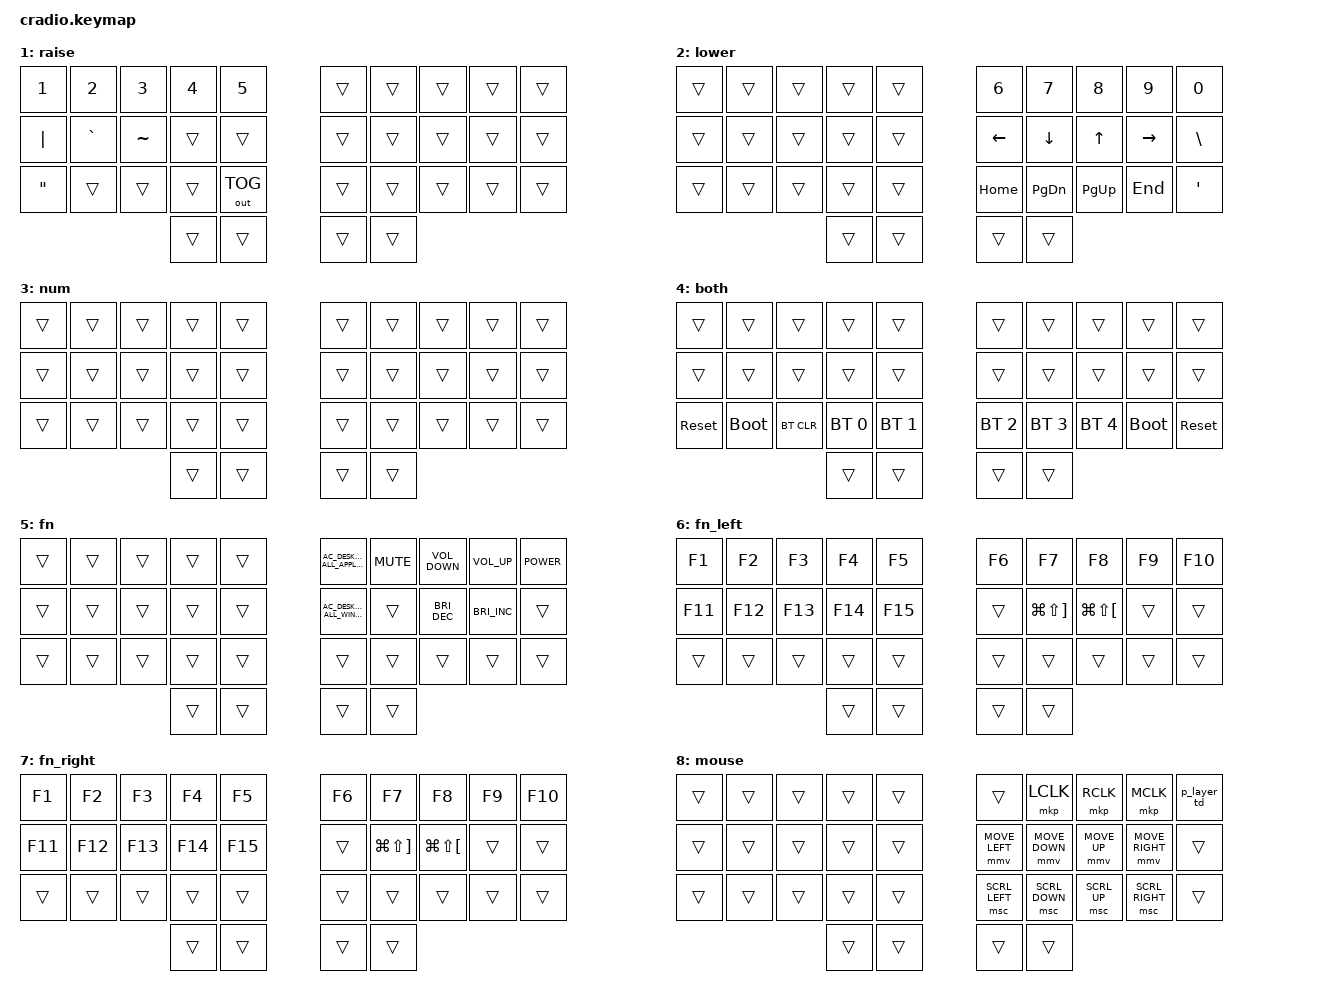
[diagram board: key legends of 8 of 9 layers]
// Copyright (c) 2022 The ZMK Contributors
// SPDX-License-Identifier: MIT


#define ZMK_POINTING_DEFAULT_MOVE_VAL 1500  // default: 600
#define ZMK_POINTING_DEFAULT_SCRL_VAL 20    // default: 10

#include <behaviors.dtsi>
#include <behaviors/mouse_keys.dtsi>
#include <dt-bindings/zmk/keys.h>
#include <dt-bindings/zmk/bt.h>
#include <dt-bindings/zmk/pointing.h>
#include <dt-bindings/zmk/outputs.h>

// Home row mods macro
#define HRML(k1,k2,k3,k4) &ht LSHFT k1  &ht LALT k2  &ht LCTRL k3  &ht LGUI k4
#define HRMR(k1,k2,k3,k4) &ht RGUI k1  &ht RCTRL k2  &ht RALT k3  &ht RSHFT k4

/ {
    combos {
        compatible = "zmk,combos";

        esc {
            timeout-ms = <50>;
            key-positions = <0 1>;
            bindings = <&kp ESC>;
        };

        esc_2 {
            timeout-ms = <50>;
            key-positions = <1 2>;
            bindings = <&kp ESC>;
        };

        backspace_or_delete {
            timeout-ms = <50>;
            key-positions = <7 8>;
            bindings = <&backspace_or_delete>;
        };

        tab {
            timeout-ms = <50>;
            key-positions = <11 12>;
            bindings = <&kp TAB>;
        };

        parenopenorless {
            timeout-ms = <50>;
            key-positions = <16 17>;
            bindings = <&paren_or_less_than>;
        };

        parencloseorgreater {
            timeout-ms = <50>;
            key-positions = <17 18>;
            bindings = <&paren_or_greather_than>;
        };

        copy {
            timeout-ms = <50>;
            key-positions = <21 22>;
            bindings = <&kp LG(C)>;
        };

        paste {
            timeout-ms = <50>;
            key-positions = <22 23>;
            bindings = <&kp LG(V)>;
        };
        
        cut {
            timeout-ms = <50>;
            key-positions = <21 23>;
            bindings = <&kp LG(X)>;
        };

        paste_maccy {
            timeout-ms = <50>;
            key-positions = <21 22 23>;
            bindings = <&kp LG(LS(C))>;
        };

        lbkt_or_lbrc {
            timeout-ms = <50>;
            key-positions = <26 27>;
            bindings = <&lbkt_or_lbrc>;
        };

        rbkt_or_rbrc {
            timeout-ms = <50>;
            key-positions = <27 28>;
            bindings = <&rbkt_or_rbrc>;
        };

        admiracion {
            timeout-ms = <50>;
            key-positions = <0 10>;
            bindings = <&kp EXCL>;
        }; 

        arroba {
            timeout-ms = <50>;
            key-positions = <1 11>;
            bindings = <&kp AT>;
        }; 

        michi {
            timeout-ms = <50>;
            key-positions = <2 12>;
            bindings = <&kp HASH>;
        }; 

        dollar {
            timeout-ms = <50>;
            key-positions = <3 13>;
            bindings = <&kp DLLR>;
        }; 

        percent {
            timeout-ms = <50>;
            key-positions = <4 14>;
            bindings = <&kp PRCNT>;
        }; 

        circun {
            timeout-ms = <50>;
            key-positions = <5 15>;
            bindings = <&kp CARET>;
        }; 

        plus {
            timeout-ms = <50>;
            key-positions = <6 16>;
            bindings = <&kp PLUS>;
        }; 

        asterisk {
            timeout-ms = <50>;
            key-positions = <7 17>;
            bindings = <&kp STAR>;
        }; 

        ampersand {
            timeout-ms = <50>;
            key-positions = <8 18>;
            bindings = <&kp AMPS>;
        }; 



        toggle_layer_mouse {
            timeout-ms = <50>;
            key-positions = <8 9>;
            bindings = <&tog 8>;
        }; 

        toggle_layer_num {
            timeout-ms = <50>;
            key-positions = <28 29>;
            bindings = <&tog 3>;
        };


        grave {
            timeout-ms = <50>;
            key-positions = <11 21>;
            bindings = <&kp GRAVE>;
        }; 
        backslash {
            timeout-ms = <50>;
            key-positions = <12 22>;
            bindings = <&kp BSLH>;
        }; 
        equal {
            timeout-ms = <50>;
            key-positions = <13 23>;
            bindings = <&kp EQUAL>;
        }; 
        virgulilla {
            timeout-ms = <50>;
            key-positions = <14 24>;
            bindings = <&kp TILDE>;
        }; 
        underscore {
            timeout-ms = <50>;
            key-positions = <15 25>;
            bindings = <&kp UNDER>;
        }; 
        minus {
            timeout-ms = <50>;
            key-positions = <16 26>;
            bindings = <&kp MINUS>;
        }; 
        slash {
            timeout-ms = <50>;
            key-positions = <17 27>;
            bindings = <&kp SLASH>;
        }; 
        pipe {
            timeout-ms = <50>;
            key-positions = <17 27>;
            bindings = <&kp BSLH>;
        }; 
        

        parentesis_angles_combo {
            timeout-ms = <50>;
            key-positions = <16 17 18>;
            bindings = <&paren_or_less_than_full>;
        };

        bracket_llaves_combo {
            timeout-ms = <50>;
            key-positions = <26 27 28>;
            bindings = <&lbkt_or_lbrc_full>;
        };

        caps_word {
            timeout-ms = <50>;
            key-positions = <14 15>;
            bindings = <&caps_word>;
        };

        leader_leader_s {
            timeout-ms = <50>;
            bindings = <&leader_leader_s>;
            key-positions = <13 16>;
        };

        cmd_shift {
            timeout-ms = <50>;
            bindings = <&kp LS(LGUI)>;
            key-positions = <10 30>;
        };
    };

    macros {
        leader_leader_s: leader_leader {
            compatible = "zmk,behavior-macro";
            #binding-cells = <0>;
            bindings = <&kp ESCAPE &kp SPACE &kp SPACE &kp S>;
            label = "LEADER_LEADER";
        };

        parentesis_full: parentesis_full {
            compatible = "zmk,behavior-macro";
            #binding-cells = <0>;
            bindings = <&kp LPAR &kp RPAR>;
            label = "PARENTESIS_FULL";
        };

        less_greater_full: less_greater_full {
            compatible = "zmk,behavior-macro";
            #binding-cells = <0>;
            bindings = <&kp LT &kp GT>;
            label = "LESS_GREATER_FULL";
        };

        llaves_full: llaves_full {
            compatible = "zmk,behavior-macro";
            #binding-cells = <0>;
            bindings = <&kp LBRC &kp RBRC>;
            label = "LLAVES_FULL";
        };

        corchetes_full: corchetes_full {
            compatible = "zmk,behavior-macro";
            #binding-cells = <0>;
            bindings = <&kp LBKT &kp RBKT>;
            label = "CORCHETES_FULL";
        };
    };

    
    behaviors {
        ht: hold_tap {
            compatible = "zmk,behavior-hold-tap";
            #binding-cells = <2>;
            flavor = "tap-preferred";
            tapping-term-ms = <220>;
            quick-tap-ms = <150>;
            require-prior-idle-ms = <100>;
            bindings = <&kp>, <&kp>;
        };
        ht2: hold_tap_2 {
            compatible = "zmk,behavior-hold-tap";
            #binding-cells = <2>;
            flavor = "tap-preferred";
            tapping-term-ms = <220>;
            quick-tap-ms = <150>;
            require-prior-idle-ms = <100>;
            bindings = <&sl>, <&kp>;
        };
        
        ht2hold: hold_tap_2_hold_preferred {
            compatible = "zmk,behavior-hold-tap";
            #binding-cells = <2>;
            flavor = "hold-preferred";
            tapping-term-ms = <220>;
            quick-tap-ms = <150>;
            require-prior-idle-ms = <100>;
            bindings = <&sl>, <&kp>;
        };

        paren_or_less_than: paren_or_less_than {
            #binding-cells = <0>;
            compatible = "zmk,behavior-mod-morph";
            label = "PAREN_OR_LESS_THAN";
            bindings = <&kp LPAR>, <&kp LT>;
            mods = <(MOD_LSFT | MOD_RSFT)>;
        };

        paren_or_greather_than: paren_or_greather_than {
            #binding-cells = <0>;
            compatible = "zmk,behavior-mod-morph";
            label = "PAREN_OR_GREATHER_THAN";
            bindings = <&kp RPAR>, <&kp GT>;
            mods = <(MOD_LSFT | MOD_RSFT)>;
        };

        lbkt_or_lbrc: lbkt_or_lbrc {
            #binding-cells = <0>;
            compatible = "zmk,behavior-mod-morph";
            label = "lbkt_or_lbrc";
            bindings = <&kp LBKT>, <&kp LBRC>;
            mods = <(MOD_LSFT | MOD_RSFT)>;
        };

        rbkt_or_rbrc: rbkt_or_rbrc {
            #binding-cells = <0>;
            compatible = "zmk,behavior-mod-morph";
            label = "rbkt_or_rbrc";
            bindings = <&kp RBKT>, <&kp RBRC>;
            mods = <(MOD_LSFT | MOD_RSFT)>;
        };
        
        
        paren_or_less_than_full: paren_or_less_than_full {
            #binding-cells = <0>;
            compatible = "zmk,behavior-mod-morph";
            label = "PAREN_OR_LESS_THAN_FULL";
            bindings = <&parentesis_full>, <&less_greater_full>;
            mods = <(MOD_LSFT | MOD_RSFT)>;
        };
        
        lbkt_or_lbrc_full: lbkt_or_lbrc_full {
            #binding-cells = <0>;
            compatible = "zmk,behavior-mod-morph";
            label = "lbkt_or_lbrc_full";
            bindings = <&corchetes_full>, <&llaves_full>;
            mods = <(MOD_LSFT | MOD_RSFT)>;
        };

        backspace_or_delete: backspace_or_delete {
            compatible = "zmk,behavior-mod-morph";
            #binding-cells = <0>;
            bindings = <&kp BACKSPACE>, <&kp DELETE>;
            mods = <(MOD_LSFT|MOD_RSFT)>;
            keep-mods = <(MOD_RSFT)>;
        };

        p_layer_td: p_layer_td {
            compatible = "zmk,behavior-tap-dance";
            label = "P_LAYER_TD";
            #binding-cells = <0>;
            tapping-term-ms = <200>; // Tiempo en ms para detectar el doble toque. Ajusta si es necesario.
            bindings = <&kp P>, <&tog 8>; // <un toque>, <dos toques>
        };
    };

    conditional_layers {
        compatible = "zmk,conditional-layers";
        tri_layer {
            if-layers = <6 7>;
            then-layer = <4>;
        };
    };

    keymap {
        compatible = "zmk,keymap";
        default_layer {
            bindings = <
        //╭──────────┬──────────┬──────────┬──────────┬──────────╮   ╭──────────┬──────────┬──────────┬──────────┬──────────╮
        //│  Q       │  W       │  E       │  R       │  T       │   │  Y       │  U       │  I       │  O       │  P       │
            &kp Q      &kp W      &kp E      &kp R      &kp T          &kp Y      &kp U      &kp I      &kp O      &kp P
        //├──────────┼──────────┼──────────┼──────────┼──────────┤   ├──────────┼──────────┼──────────┼──────────┼──────────┤
        //│  A       │  S       │  D       │  F       │  G       │   │  H       │  J       │  K       │  L       │ ; :      │
            HRML(A,        S,         D,         F)     &kp G          &kp H      HRMR(J,     K,         L,        SEMI)
        //├──────────┼──────────┼──────────┼──────────┼──────────┤   ├──────────┼──────────┼──────────┼──────────┼──────────┤
        //│  Z       │  X       │  C       │  V       │  B       │   │  N       │  M       │ , <      │ . >      │ / ?      │
            &ht2hold 6 Z      &kp X   &kp C      &kp V      &kp B          &kp N      &kp M      &kp COMMA  &ht2 5 DOT  &ht2hold 7 FSLH
        //╰──────────┴──────────┴──────────┼──────────┼──────────┤   ├──────────┼──────────┼──────────┴──────────┴──────────╯
                                            &kp TAB   &sl 1   &ht2hold 2 ENTER  &kp SPACE 
        //                                 ╰──────────┴──────────╯   ╰──────────┴──────────╯
            >;
        };

        raise {
        bindings = <
            &kp NUMBER_1  &kp NUMBER_2  &kp NUMBER_3  &kp NUMBER_4  &kp NUMBER_5     &trans     &trans     &trans    &trans    &trans
            &kp PIPE      &kp GRAVE     &kp TILDE     &trans        &trans           &trans     &trans     &trans    &trans    &trans
            &kp DOUBLE_QUOTES     &trans        &trans        &trans        &out OUT_TOG           &trans     &trans     &trans    &trans    &trans
                                                      &trans        &trans           &trans     &trans
        >;
        };

        lower {
        bindings = <
            &trans   &trans  &trans  &trans  &trans    &kp NUMBER_6    &kp NUMBER_7    &kp NUMBER_8  &kp NUMBER_9     &kp NUMBER_0
            &trans   &trans  &trans  &trans  &trans    &kp LEFT_ARROW  &kp DOWN_ARROW  &kp UP_ARROW  &kp RIGHT_ARROW  &kp BSLH
            &trans   &trans  &trans  &trans  &trans    &kp HOME        &kp PG_DN       &kp PG_UP     &kp END          &kp APOS
                                     &trans  &trans    &trans          &trans
        >;
        };

        num {
        bindings = <
            &trans   &trans   &trans   &trans   &trans   &trans  &trans            &trans            &trans  &trans
            &trans   &trans   &trans   &trans   &trans   &trans  &trans            &trans            &trans  &trans
            &trans   &trans   &trans   &trans   &trans   &trans  &trans            &trans            &trans  &trans
                                             &trans     &trans    &trans     &trans
        >;
        };
        
        both {
        bindings = <
            &trans      &trans        &trans      &trans        &trans        &trans        &trans        &trans        &trans       &trans
            &trans      &trans        &trans      &trans        &trans        &trans        &trans        &trans        &trans       &trans
            &sys_reset  &bootloader   &bt BT_CLR  &bt BT_SEL 0  &bt BT_SEL 1  &bt BT_SEL 2  &bt BT_SEL 3  &bt BT_SEL 4  &bootloader  &sys_reset
                                                                &trans        &trans        &trans        &trans
        >;
        };

        fn {
        bindings = <
            &trans   &trans  &trans  &trans  &trans    &kp C_AC_DESKTOP_SHOW_ALL_APPLICATIONS  &kp C_MUTE            &kp C_VOLUME_DOWN     &kp C_VOLUME_UP        &kp C_POWER
            &trans   &trans  &trans  &trans  &trans    &kp C_AC_DESKTOP_SHOW_ALL_WINDOWS       &trans                &kp C_BRIGHTNESS_DEC  &kp C_BRIGHTNESS_INC  &trans
            &trans   &trans  &trans  &trans  &trans    &trans                                  &trans                &trans                &trans  &trans
                                     &trans  &trans    &trans                                  &trans
        >;
        };

        //special {
        //bindings = <
        //    &kp ESCAPE  &kp LG(W)    &kp LG(E)  &kp LG(R)  &kp LG(T)    &trans         &trans        &trans         &kp LG(O)      &kp LG(P)
        //    &kp LG(A)   &kt LG(TAB)  &trans     &kp LG(F)  &kp LG(G)    &kp LG(MINUS)  &kp LG(PLUS)  &kp LG(K)      &kp LG(L)      &trans
        //    &kp LG(Z)   &kp LG(X)    &kp LG(C)  &kp LG(V)  &kp LG(B)    &trans         &trans        &trans         &kp LG(GRAVE)  &kp LG(APOS)
        //                                        &trans     &trans       &trans         &trans
        //>;
        //};
        
        fn_left {
        bindings = <
            &kp F1   &kp F2   &kp F3   &kp F4   &kp F5   &kp F6  &kp F7            &kp F8            &kp F9  &kp F10 
            &kp F11  &kp F12  &kp F13  &kp F14  &kp F15  &trans  &kp LG(LS(RBKT))  &kp LG(LS(LBKT))  &trans  &trans
            &trans   &trans   &trans   &trans   &trans   &trans  &trans            &trans            &trans  &trans
                                       &trans   &trans   &trans  &trans
        >;
        };
        
        fn_right {
        bindings = <
            &kp F1   &kp F2   &kp F3   &kp F4   &kp F5   &kp F6  &kp F7            &kp F8            &kp F9  &kp F10 
            &kp F11  &kp F12  &kp F13  &kp F14  &kp F15  &trans  &kp LG(LS(RBKT))  &kp LG(LS(LBKT))  &trans  &trans
            &trans   &trans   &trans   &trans   &trans   &trans  &trans            &trans            &trans  &trans
                                       &trans   &trans   &trans  &trans
        >;
        };
        
        mouse {
        bindings = <
            &trans   &trans    &trans  &trans  &trans   &trans          &mkp LCLK       &mkp RCLK     &mkp MCLK        &p_layer_td
            &trans   &trans    &trans  &trans  &trans   &mmv MOVE_LEFT  &mmv MOVE_DOWN  &mmv MOVE_UP  &mmv MOVE_RIGHT  &trans
            &trans   &trans    &trans  &trans  &trans   &msc SCRL_LEFT  &msc SCRL_DOWN  &msc SCRL_UP  &msc SCRL_RIGHT  &trans
                                       &trans  &trans   &trans  &trans
        >;
        };
    };
};
